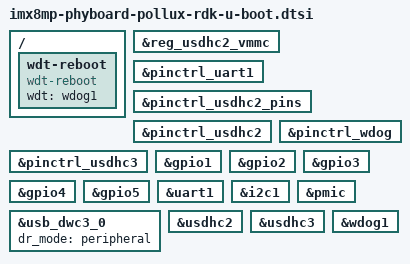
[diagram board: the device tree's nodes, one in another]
// SPDX-License-Identifier: GPL-2.0-or-later
/*
 * Copyright (C) 2020 PHYTEC Messtechnik GmbH
 * Author: Teresa Remmet <t.remmet@phytec.de>
 */

#include "imx8mp-u-boot.dtsi"

/ {
	wdt-reboot {
		compatible = "wdt-reboot";
		wdt = <&wdog1>;
		bootph-pre-ram;
	};
};

&reg_usdhc2_vmmc {
	bootph-pre-ram;
};

&pinctrl_uart1 {
	bootph-pre-ram;
};

&pinctrl_usdhc2_pins {
	bootph-pre-ram;
};

&pinctrl_usdhc2 {
	bootph-pre-ram;
};

&pinctrl_usdhc3 {
	bootph-pre-ram;
};

&pinctrl_wdog {
	bootph-pre-ram;
};

&gpio1 {
	bootph-pre-ram;
};

&gpio2 {
	bootph-pre-ram;
};

&gpio3 {
	bootph-pre-ram;
};

&gpio4 {
	bootph-pre-ram;
};

&gpio5 {
	bootph-pre-ram;
};

&uart1 {
	bootph-pre-ram;
};

&i2c1 {
	bootph-pre-ram;
};

&pmic {
	bootph-pre-ram;
};

&usb_dwc3_0 {
	dr_mode = "peripheral";
};

&usdhc2 {
	bootph-pre-ram;
};

&usdhc3 {
	bootph-pre-ram;
};

&wdog1 {
	bootph-pre-ram;
};
